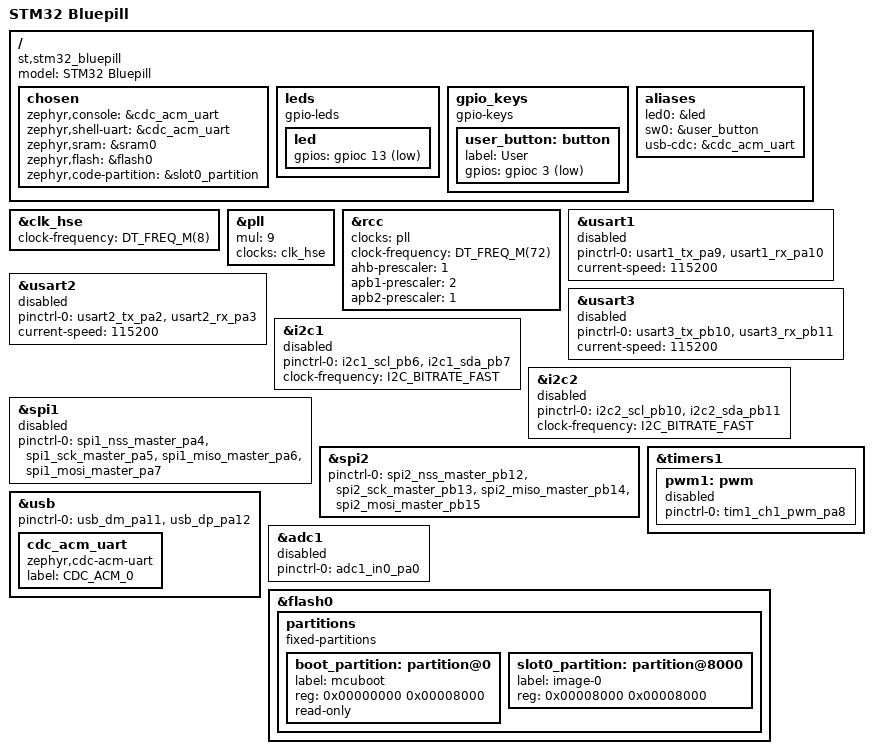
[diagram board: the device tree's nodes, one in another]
/*
 * Copyright (c) 2017, embedjournal.com
 * Copyright (c) 2021-2022, thedjnK
 *
 * SPDX-License-Identifier: Apache-2.0
 */

/dts-v1/;
#include <st/f1/stm32f103X8.dtsi>
#include <st/f1/stm32f103r(8-b)tx-pinctrl.dtsi>

/ {
	model = "STM32 Bluepill";
	compatible = "st,stm32_bluepill", "st,stm32f103c8";

	chosen {
		zephyr,console = &cdc_acm_uart;
		zephyr,shell-uart = &cdc_acm_uart;
		zephyr,sram = &sram0;
		zephyr,flash = &flash0;
		zephyr,code-partition = &slot0_partition;
	};

	leds {
		compatible = "gpio-leds";
		led: led {
			gpios = <&gpioc 13 GPIO_ACTIVE_LOW>;
		};
	};

	gpio_keys {
		compatible = "gpio-keys";
		user_button: button {
			label = "User";
			gpios = <&gpioc 3 GPIO_ACTIVE_LOW>;
		};
	};

	aliases {
		led0 = &led;
		sw0 = &user_button;
		usb-cdc = &cdc_acm_uart;
	};
};

&clk_hse {
	clock-frequency = <DT_FREQ_M(8)>;
	status = "okay";
};

&pll {
	mul = <9>;
	clocks = <&clk_hse>;
	status = "okay";
};

&rcc {
	clocks = <&pll>;
	clock-frequency = <DT_FREQ_M(72)>;
	ahb-prescaler = <1>;
	apb1-prescaler = <2>;
	apb2-prescaler = <1>;
};

&usart1 {
	pinctrl-0 = <&usart1_tx_pa9 &usart1_rx_pa10>;
	current-speed = <115200>;
	status = "disabled";
};

&usart2 {
	pinctrl-0 = <&usart2_tx_pa2 &usart2_rx_pa3>;
	current-speed = <115200>;
	status = "disabled";
};

&usart3 {
	pinctrl-0 = <&usart3_tx_pb10 &usart3_rx_pb11>;
	current-speed = <115200>;
	status = "disabled";
};

&i2c1 {
	pinctrl-0 = < &i2c1_scl_pb6 &i2c1_sda_pb7 >;
	status = "disabled";
	clock-frequency = <I2C_BITRATE_FAST>;
};

&i2c2 {
	pinctrl-0 = < &i2c2_scl_pb10 &i2c2_sda_pb11 >;
	status = "disabled";
	clock-frequency = <I2C_BITRATE_FAST>;
};

&spi1 {
	pinctrl-0 = <&spi1_nss_master_pa4 &spi1_sck_master_pa5
		     &spi1_miso_master_pa6 &spi1_mosi_master_pa7>;
	status = "disabled";
};

&spi2 {
	pinctrl-0 = <&spi2_nss_master_pb12 &spi2_sck_master_pb13
		     &spi2_miso_master_pb14 &spi2_mosi_master_pb15>;
	status = "okay";
};

&timers1 {
	status = "okay";

	pwm1: pwm {
		status = "disabled";
		pinctrl-0 = <&tim1_ch1_pwm_pa8>;
	};
};

&usb {
	pinctrl-0 = <&usb_dm_pa11 &usb_dp_pa12>;
	status = "okay";

	cdc_acm_uart: cdc_acm_uart {
		compatible = "zephyr,cdc-acm-uart";
		label = "CDC_ACM_0";
	};
};

&adc1 {
	pinctrl-0 = <&adc1_in0_pa0>;
	status = "disabled";
};

&flash0 {
	partitions {
		compatible = "fixed-partitions";
		#address-cells = <1>;
		#size-cells = <1>;

		boot_partition: partition@0 {
			label = "mcuboot";
			reg = <0x00000000 0x00008000>;
			read-only;
		};

		slot0_partition: partition@8000 {
			label = "image-0";
			reg = <0x00008000 0x00008000>;
		};
	};
};

